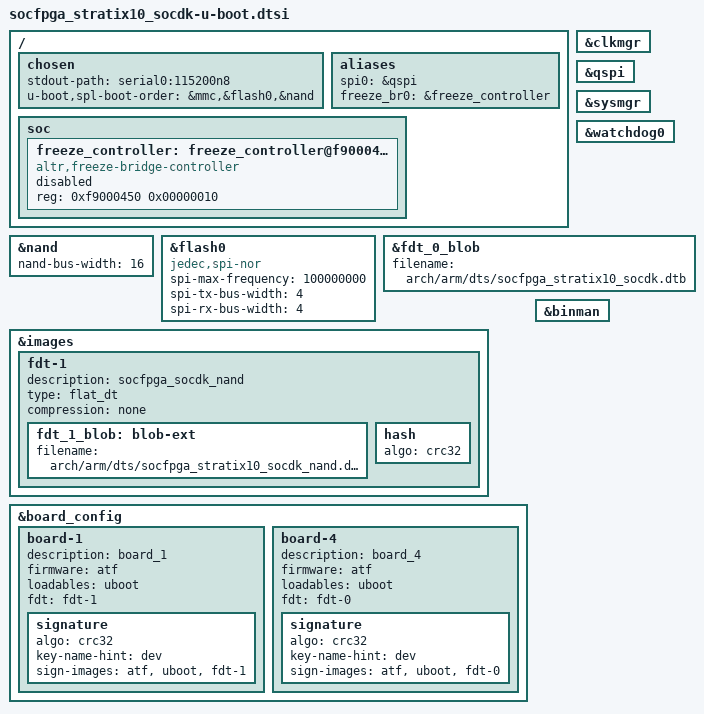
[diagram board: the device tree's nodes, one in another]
// SPDX-License-Identifier: GPL-2.0+
/*
 * U-Boot additions
 *
 * Copyright (C) 2019-2022 Intel Corporation <www.intel.com>
 */

#include "socfpga_stratix10-u-boot.dtsi"

/{
	chosen {
		stdout-path = "serial0:115200n8";
		u-boot,spl-boot-order = &mmc,&flash0,&nand;
	};

	aliases {
		spi0 = &qspi;
		freeze_br0 = &freeze_controller;
	};

	soc {
		freeze_controller: freeze_controller@f9000450 {
			compatible = "altr,freeze-bridge-controller";
			reg = <0xf9000450 0x00000010>;
			status = "disabled";
		};
	};
};

&clkmgr {
	bootph-all;
};

&nand {
	status = "okay";
	nand-bus-width = <16>;
	bootph-all;
};

&qspi {
	status = "okay";
	bootph-all;
};

&flash0 {
	compatible = "jedec,spi-nor";
	spi-max-frequency = <100000000>;
	spi-tx-bus-width = <4>;
	spi-rx-bus-width = <4>;
	bootph-all;
};

&sysmgr {
	bootph-all;
};

&watchdog0 {
	status = "okay";
	bootph-all;
};

&fdt_0_blob {
	filename = "arch/arm/dts/socfpga_stratix10_socdk.dtb";
};

&images {
	fdt-1 {
		description = "socfpga_socdk_nand";
		type = "flat_dt";
		compression = "none";
		fdt_1_blob: blob-ext {
			filename = "arch/arm/dts/socfpga_stratix10_socdk_nand.dtb";
		};
		hash {
			algo = "crc32";
		};
	};
};

&board_config {
	board-1 {
		description = "board_1";
		firmware = "atf";
		loadables = "uboot";
		fdt = "fdt-1";
		signature {
			algo = "crc32";
			key-name-hint = "dev";
			sign-images = "atf", "uboot", "fdt-1";
		};
	};

	board-4 {
		description = "board_4";
		firmware = "atf";
		loadables = "uboot";
		fdt = "fdt-0";
		signature {
			algo = "crc32";
			key-name-hint = "dev";
			sign-images = "atf", "uboot", "fdt-0";
		};
	};
};

&binman {
	/delete-node/ kernel;
};
